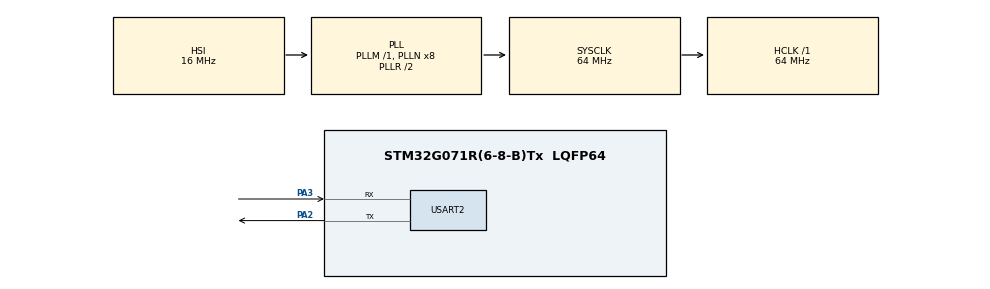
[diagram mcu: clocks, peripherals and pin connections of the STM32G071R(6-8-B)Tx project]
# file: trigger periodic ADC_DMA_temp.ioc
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ADC1.Channel-0\#ChannelRegularConversion=ADC_CHANNEL_TEMPSENSOR
ADC1.ClockPrescaler=ADC_CLOCK_ASYNC_DIV32
ADC1.ContinuousConvMode=ENABLE
ADC1.DMAContinuousRequests=ENABLE
ADC1.NbrOfConversionFlag=1
ADC1.Rank-0\#ChannelRegularConversion=1
ADC1.SamplingTime-0\#ChannelRegularConversion=ADC_SAMPLINGTIME_COMMON_1
ADC1.SamplingTimeCommon1=ADC_SAMPLETIME_12CYCLES_5
ADC1.SelectedChannel=ADC_CHANNEL_TEMPSENSOR
ADC1.master=1
Dma.ADC1.0.Direction=DMA_PERIPH_TO_MEMORY
Dma.ADC1.0.EventEnable=DISABLE
Dma.ADC1.0.Instance=DMA1_Channel1
Dma.ADC1.0.MemDataAlignment=DMA_MDATAALIGN_HALFWORD
Dma.ADC1.0.MemInc=DMA_MINC_ENABLE
Dma.ADC1.0.Mode=DMA_CIRCULAR
Dma.ADC1.0.PeriphDataAlignment=DMA_PDATAALIGN_HALFWORD
Dma.ADC1.0.PeriphInc=DMA_PINC_DISABLE
Dma.ADC1.0.Polarity=HAL_DMAMUX_REQ_GEN_RISING
Dma.ADC1.0.Priority=DMA_PRIORITY_LOW
Dma.ADC1.0.RequestNumber=1
Dma.ADC1.0.SignalID=NONE
Dma.ADC1.0.SyncEnable=DISABLE
Dma.ADC1.0.SyncPolarity=HAL_DMAMUX_SYNC_NO_EVENT
Dma.ADC1.0.SyncRequestNumber=1
Dma.ADC1.0.SyncSignalID=NONE
Dma.Request0=ADC1
Mcu.Family=STM32G0
Mcu.Name=STM32G071R(6-8-B)Tx
Mcu.Package=LQFP64
NVIC.ADC1_COMP_IRQn=true\:0\:0\:false\:false\:true\:true\:true\:true
NVIC.DMA1_Channel1_IRQn=true\:0\:0\:false\:false\:true\:false\:true\:true
PA13.Mode=Serial_Wire
PA13.Signal=SYS_SWDIO
PA14-BOOT0.Mode=Serial_Wire
PA14-BOOT0.Signal=SYS_SWCLK
PA2.Mode=Asynchronous
PA2.Signal=USART2_TX
PA3.Mode=Asynchronous
PA3.Signal=USART2_RX
PC14-OSC32_IN\ (PC14).Mode=LSE-External-Oscillator
PC14-OSC32_IN\ (PC14).Signal=RCC_OSC32_IN
PC15-OSC32_OUT\ (PC15).Mode=LSE-External-Oscillator
PC15-OSC32_OUT\ (PC15).Signal=RCC_OSC32_OUT
PF0-OSC_IN\ (PF0).Mode=HSE-External-Oscillator
PF0-OSC_IN\ (PF0).Signal=RCC_OSC_IN
PF1-OSC_OUT\ (PF1).Mode=HSE-External-Oscillator
PF1-OSC_OUT\ (PF1).Signal=RCC_OSC_OUT
ProjectManager.HeapSize=0x200
ProjectManager.StackSize=0x400
ProjectManager.TargetToolchain=STM32CubeIDE
RCC.ADCFreq_Value=64000000
RCC.AHBFreq_Value=64000000
RCC.CortexFreq_Value=64000000
RCC.EXTERNAL_CLOCK_VALUE=12288000
RCC.HCLKFreq_Value=64000000
RCC.HSE_VALUE=8000000
RCC.HSI_VALUE=16000000
RCC.PLLP=RCC_PLLP_DIV4
RCC.SYSCLKFreq_VALUE=64000000
RCC.SYSCLKSource=RCC_SYSCLKSOURCE_PLLCLK
RCC.VCOOutputFreq_Value=128000000
TIM2.Channel-PWM\ Generation1\ No\ Output=TIM_CHANNEL_1
TIM2.Period=10000-1
TIM2.Prescaler=64-1
TIM2.TIM_MasterOutputTrigger=TIM_TRGO_UPDATE
USART2.VirtualMode-Asynchronous=VM_ASYNC
VP_ADC1_TempSens_Input.Mode=IN-TempSens
VP_TIM2_VS_no_output1.Mode=PWM Generation1 No Output
board=NUCLEO-G071RB

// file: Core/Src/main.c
/* USER CODE BEGIN Header */
/**
  ******************************************************************************
  * @file           : main.c
  * @brief          : Main program body
  ******************************************************************************
  * @attention
  *
  * Copyright (c) 2026 STMicroelectronics.
  * All rights reserved.
  *
  * This software is licensed under terms that can be found in the LICENSE file
  * in the root directory of this software component.
  * If no LICENSE file comes with this software, it is provided AS-IS.
  *
  ******************************************************************************
  */
/* USER CODE END Header */
#include "main.h"

/* USER CODE BEGIN Includes */
#include <stdio.h>
#define N 100
/* USER CODE END Includes */

ADC_HandleTypeDef hadc1;
DMA_HandleTypeDef hdma_adc1;

TIM_HandleTypeDef htim2;

UART_HandleTypeDef huart2;

void SystemClock_Config(void);
static void MX_DMA_Init(void);
static void MX_GPIO_Init(void);
static void MX_ADC1_Init(void);
static void MX_TIM2_Init(void);
static void MX_USART2_UART_Init(void);

/* USER CODE BEGIN 0 */

uint16_t adc_data[N];

float temperature[N];
uint32_t index1 = 0;
volatile uint8_t half_ready = 0;
volatile uint8_t full_ready = 0;

int _write(int file, char *ptr, int len)
{
	HAL_UART_Transmit(&huart2,(uint8_t*)ptr,len,HAL_MAX_DELAY);  //If you need to use "printf" for displaying output
	return len;												     //If you need to use 'Transmit', you don't need to have..
}

/* USER CODE END 0 */

int main(void)
{

  /* MCU Configuration--------------------------------------------------------*/

  /* Reset of all peripherals, Initializes the Flash interface and the Systick. */
  HAL_Init();

  /* Configure the system clock */
  SystemClock_Config();

  /* Initialize all configured peripherals */
  MX_DMA_Init();
  MX_GPIO_Init();
  MX_ADC1_Init();
  MX_TIM2_Init();
  MX_USART2_UART_Init();
  /* USER CODE BEGIN 2 */
  HAL_ADCEx_Calibration_Start(&hadc1);
  HAL_ADC_Start_DMA(&hadc1 , (uint32_t *)adc_data , N);
  HAL_TIM_Base_Start_IT(&htim2);
  /* USER CODE END 2 */

  /* Infinite loop */
  while (1)
  {
	  if(half_ready && full_ready){
		  half_ready = full_ready = 0;
		  temperature[index1] = __HAL_ADC_CALC_TEMPERATURE(3300, adc_data[index1], ADC_RESOLUTION_12B);
		  index1++;
		  	  if(index1 % 100 == 0){
		      		 printf("ADC1: %d  temp : %f \r\n", adc_data[index1] , temperature[index1]);
		      	     index1 = 0;
		       }
	     }

  }
}

void SystemClock_Config(void)
{
  RCC_OscInitTypeDef RCC_OscInitStruct = {0};
  RCC_ClkInitTypeDef RCC_ClkInitStruct = {0};

  /** Configure the main internal regulator output voltage
  */
  HAL_PWREx_ControlVoltageScaling(PWR_REGULATOR_VOLTAGE_SCALE1);

  /** Initializes the RCC Oscillators according to the specified parameters
  * in the RCC_OscInitTypeDef structure.
  */
  RCC_OscInitStruct.OscillatorType = RCC_OSCILLATORTYPE_HSI;
  RCC_OscInitStruct.HSIState = RCC_HSI_ON;
  RCC_OscInitStruct.HSIDiv = RCC_HSI_DIV1;
  RCC_OscInitStruct.HSICalibrationValue = RCC_HSICALIBRATION_DEFAULT;
  RCC_OscInitStruct.PLL.PLLState = RCC_PLL_ON;
  RCC_OscInitStruct.PLL.PLLSource = RCC_PLLSOURCE_HSI;
  RCC_OscInitStruct.PLL.PLLM = RCC_PLLM_DIV1;
  RCC_OscInitStruct.PLL.PLLN = 8;
  RCC_OscInitStruct.PLL.PLLP = RCC_PLLP_DIV4;
  RCC_OscInitStruct.PLL.PLLQ = RCC_PLLQ_DIV2;
  RCC_OscInitStruct.PLL.PLLR = RCC_PLLR_DIV2;
  if (HAL_RCC_OscConfig(&RCC_OscInitStruct) != HAL_OK)
  {
    Error_Handler();
  }

  /** Initializes the CPU, AHB and APB buses clocks
  */
  RCC_ClkInitStruct.ClockType = RCC_CLOCKTYPE_HCLK|RCC_CLOCKTYPE_SYSCLK
                              |RCC_CLOCKTYPE_PCLK1;
  RCC_ClkInitStruct.SYSCLKSource = RCC_SYSCLKSOURCE_PLLCLK;
  RCC_ClkInitStruct.AHBCLKDivider = RCC_SYSCLK_DIV1;
  RCC_ClkInitStruct.APB1CLKDivider = RCC_HCLK_DIV1;

  if (HAL_RCC_ClockConfig(&RCC_ClkInitStruct, FLASH_LATENCY_2) != HAL_OK)
  {
    Error_Handler();
  }
}

static void MX_ADC1_Init(void)
{

  ADC_ChannelConfTypeDef sConfig = {0};

  /** Configure the global features of the ADC (Clock, Resolution, Data Alignment and number of conversion)
  */
  hadc1.Instance = ADC1;
  hadc1.Init.ClockPrescaler = ADC_CLOCK_ASYNC_DIV32;
  hadc1.Init.Resolution = ADC_RESOLUTION_12B;
  hadc1.Init.DataAlign = ADC_DATAALIGN_RIGHT;
  hadc1.Init.ScanConvMode = ADC_SCAN_DISABLE;
  hadc1.Init.EOCSelection = ADC_EOC_SINGLE_CONV;
  hadc1.Init.LowPowerAutoWait = DISABLE;
  hadc1.Init.LowPowerAutoPowerOff = DISABLE;
  hadc1.Init.ContinuousConvMode = ENABLE;
  hadc1.Init.NbrOfConversion = 1;
  hadc1.Init.ExternalTrigConv = ADC_SOFTWARE_START;
  hadc1.Init.ExternalTrigConvEdge = ADC_EXTERNALTRIGCONVEDGE_NONE;
  hadc1.Init.DMAContinuousRequests = ENABLE;
  hadc1.Init.Overrun = ADC_OVR_DATA_PRESERVED;
  hadc1.Init.SamplingTimeCommon1 = ADC_SAMPLETIME_12CYCLES_5;
  hadc1.Init.SamplingTimeCommon2 = ADC_SAMPLETIME_1CYCLE_5;
  hadc1.Init.OversamplingMode = DISABLE;
  hadc1.Init.TriggerFrequencyMode = ADC_TRIGGER_FREQ_HIGH;
  if (HAL_ADC_Init(&hadc1) != HAL_OK)
  {
    Error_Handler();
  }

  /** Configure Regular Channel
  */
  sConfig.Channel = ADC_CHANNEL_TEMPSENSOR;
  sConfig.Rank = ADC_REGULAR_RANK_1;
  sConfig.SamplingTime = ADC_SAMPLINGTIME_COMMON_1;
  if (HAL_ADC_ConfigChannel(&hadc1, &sConfig) != HAL_OK)
  {
    Error_Handler();
  }

}

static void MX_TIM2_Init(void)
{

  TIM_MasterConfigTypeDef sMasterConfig = {0};
  TIM_OC_InitTypeDef sConfigOC = {0};

  htim2.Instance = TIM2;
  htim2.Init.Prescaler = 64-1;
  htim2.Init.CounterMode = TIM_COUNTERMODE_UP;
  htim2.Init.Period = 10000-1;
  htim2.Init.ClockDivision = TIM_CLOCKDIVISION_DIV1;
  htim2.Init.AutoReloadPreload = TIM_AUTORELOAD_PRELOAD_DISABLE;
  if (HAL_TIM_PWM_Init(&htim2) != HAL_OK)
  {
    Error_Handler();
  }
  sMasterConfig.MasterOutputTrigger = TIM_TRGO_UPDATE;
  sMasterConfig.MasterSlaveMode = TIM_MASTERSLAVEMODE_DISABLE;
  if (HAL_TIMEx_MasterConfigSynchronization(&htim2, &sMasterConfig) != HAL_OK)
  {
    Error_Handler();
  }
  sConfigOC.OCMode = TIM_OCMODE_PWM1;
  sConfigOC.Pulse = 0;
  sConfigOC.OCPolarity = TIM_OCPOLARITY_HIGH;
  sConfigOC.OCFastMode = TIM_OCFAST_DISABLE;
  if (HAL_TIM_PWM_ConfigChannel(&htim2, &sConfigOC, TIM_CHANNEL_1) != HAL_OK)
  {
    Error_Handler();
  }

}

static void MX_USART2_UART_Init(void)
{

  huart2.Instance = USART2;
  huart2.Init.BaudRate = 115200;
  huart2.Init.WordLength = UART_WORDLENGTH_8B;
  huart2.Init.StopBits = UART_STOPBITS_1;
  huart2.Init.Parity = UART_PARITY_NONE;
  huart2.Init.Mode = UART_MODE_TX_RX;
  huart2.Init.HwFlowCtl = UART_HWCONTROL_NONE;
  huart2.Init.OverSampling = UART_OVERSAMPLING_16;
  huart2.Init.OneBitSampling = UART_ONE_BIT_SAMPLE_DISABLE;
  huart2.Init.ClockPrescaler = UART_PRESCALER_DIV1;
  huart2.AdvancedInit.AdvFeatureInit = UART_ADVFEATURE_NO_INIT;
  if (HAL_UART_Init(&huart2) != HAL_OK)
  {
    Error_Handler();
  }
  if (HAL_UARTEx_SetTxFifoThreshold(&huart2, UART_TXFIFO_THRESHOLD_1_8) != HAL_OK)
  {
    Error_Handler();
  }
  if (HAL_UARTEx_SetRxFifoThreshold(&huart2, UART_RXFIFO_THRESHOLD_1_8) != HAL_OK)
  {
    Error_Handler();
  }
  if (HAL_UARTEx_DisableFifoMode(&huart2) != HAL_OK)
  {
    Error_Handler();
  }

}

static void MX_DMA_Init(void)
{

  /* DMA controller clock enable */
  __HAL_RCC_DMA1_CLK_ENABLE();

  /* DMA interrupt init */
  /* DMA1_Channel1_IRQn interrupt configuration */
  HAL_NVIC_SetPriority(DMA1_Channel1_IRQn, 0, 0);
  HAL_NVIC_EnableIRQ(DMA1_Channel1_IRQn);

}

static void MX_GPIO_Init(void)
{

  /* GPIO Ports Clock Enable */
  __HAL_RCC_GPIOC_CLK_ENABLE();
  __HAL_RCC_GPIOF_CLK_ENABLE();
  __HAL_RCC_GPIOA_CLK_ENABLE();

}

/* USER CODE BEGIN 4 */
void HAL_ADC_ConvHalfCpltCallback(ADC_HandleTypeDef* hadc)
{
	half_ready = 1;

}
void HAL_ADC_ConvCpltCallback(ADC_HandleTypeDef* hadc)
{
    full_ready = 1;
}

/* USER CODE END 4 */

void Error_Handler(void)
{
  __disable_irq();
  while (1)
  {
  }
}
